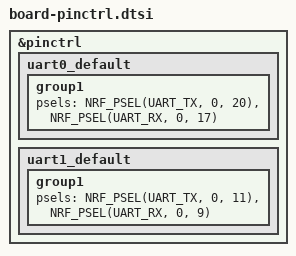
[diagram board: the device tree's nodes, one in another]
&pinctrl {
  uart0_default: uart0_default {
    group1 {
      psels = <NRF_PSEL(UART_TX, 0, 20)>,
              <NRF_PSEL(UART_RX, 0, 17)>;
    };
  };

  uart1_default: uart1_default {
    group1 {
      psels = <NRF_PSEL(UART_TX, 0, 11)>,
              <NRF_PSEL(UART_RX, 0, 9)>;
    };
  };
};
